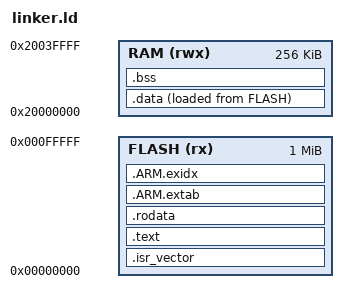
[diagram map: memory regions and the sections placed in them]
ENTRY(Reset_Handler)

MEMORY
{
    FLASH (rx)  : ORIGIN = 0x00000000, LENGTH = 1024K
    RAM   (rwx) : ORIGIN = 0x20000000, LENGTH = 256K
}

SECTIONS
{
    .isr_vector :
    {
        KEEP(*(.isr_vector))
    } > FLASH

    .text :
    {
        *(.text*)
        *(.glue_7*)
        *(.glue_7t*)
    } > FLASH

    .rodata :
    {
        *(.rodata*)
        *(.eh_frame*)
    } > FLASH

    .ARM.extab :
    {
        *(.ARM.extab* .gnu.linkonce.armextab.*)
    } > FLASH

    .ARM.exidx :
    {
        *(.ARM.exidx* .gnu.linkonce.armexidx.*)
    } > FLASH

    .data :
    {
        __data_start__ = .;
        *(.data*)
        __data_end__ = .;
    } > RAM AT > FLASH

    .bss (NOLOAD) :
    {
        __bss_start__ = .;
        *(.bss*)
        *(COMMON)
        __bss_end__ = .;
        end = .;
        __end__ = .;
    } > RAM

    __StackTop = ORIGIN(RAM) + LENGTH(RAM);
}
